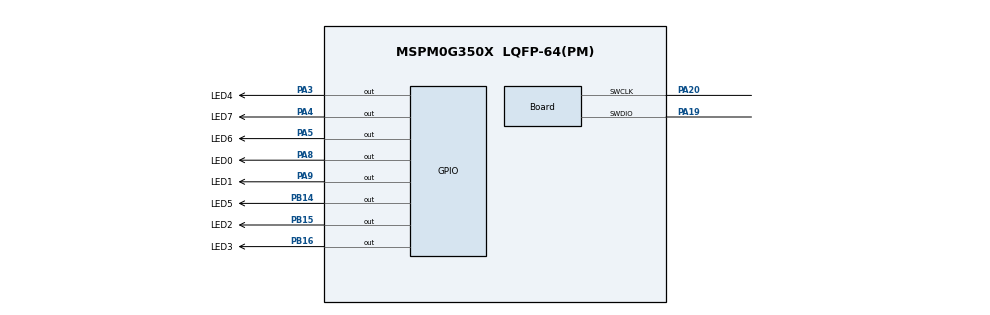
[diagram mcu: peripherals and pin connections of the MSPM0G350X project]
/**
 * @cliArgs --device "MSPM0G350X" --package "LQFP-64(PM)" --part "Default" --product "mspm0_sdk@1.20.01.06"
 * @versions {"tool":"1.18.1+3343"}
 */

/**
 * Import the modules used in this configuration.
 */
const Board         = scripting.addModule("/ti/driverlib/Board");
const GPIO          = scripting.addModule("/ti/driverlib/GPIO", {}, false);
const GPIO1         = GPIO.addInstance();
const SYSCTL        = scripting.addModule("/ti/driverlib/SYSCTL");
const ProjectConfig = scripting.addModule("/ti/project_config/ProjectConfig");

/**
 * Write custom configuration values to the imported modules.
 */
const gate7  = system.clockTree["MFCLKGATE"];
gate7.enable = true;

const gate8  = system.clockTree["MFPCLKGATE"];
gate8.enable = true;

Board.peripheral.$assign          = "DEBUGSS";
Board.peripheral.swclkPin.$assign = "PA20";
Board.peripheral.swdioPin.$assign = "PA19";

GPIO1.$name                          = "LED";
GPIO1.associatedPins.create(8);
GPIO1.associatedPins[0].initialValue = "SET";
GPIO1.associatedPins[0].assignedPin  = "8";
GPIO1.associatedPins[0].$name        = "LED0";
GPIO1.associatedPins[0].pin.$assign  = "PA8";
GPIO1.associatedPins[1].assignedPin  = "9";
GPIO1.associatedPins[1].initialValue = "SET";
GPIO1.associatedPins[1].$name        = "LED1";
GPIO1.associatedPins[1].pin.$assign  = "PA9";
GPIO1.associatedPins[2].initialValue = "SET";
GPIO1.associatedPins[2].$name        = "LED2";
GPIO1.associatedPins[2].assignedPin  = "15";
GPIO1.associatedPins[2].pin.$assign  = "PB15";
GPIO1.associatedPins[3].initialValue = "SET";
GPIO1.associatedPins[3].$name        = "LED3";
GPIO1.associatedPins[3].assignedPin  = "16";
GPIO1.associatedPins[3].pin.$assign  = "PB16";
GPIO1.associatedPins[4].initialValue = "SET";
GPIO1.associatedPins[4].$name        = "LED4";
GPIO1.associatedPins[4].assignedPin  = "3";
GPIO1.associatedPins[4].pin.$assign  = "PA3";
GPIO1.associatedPins[5].initialValue = "SET";
GPIO1.associatedPins[5].$name        = "LED5";
GPIO1.associatedPins[5].assignedPin  = "14";
GPIO1.associatedPins[5].pin.$assign  = "PB14";
GPIO1.associatedPins[6].initialValue = "SET";
GPIO1.associatedPins[6].$name        = "LED6";
GPIO1.associatedPins[6].assignedPin  = "5";
GPIO1.associatedPins[6].pin.$assign  = "PA5";
GPIO1.associatedPins[7].initialValue = "SET";
GPIO1.associatedPins[7].$name        = "LED7";
GPIO1.associatedPins[7].assignedPin  = "4";
GPIO1.associatedPins[7].pin.$assign  = "PA4";

SYSCTL.MFCLKEn     = true;
SYSCTL.MFPCLKEn    = true;
SYSCTL.clockTreeEn = true;

ProjectConfig.deviceSpin = "MSPM0G3507";
